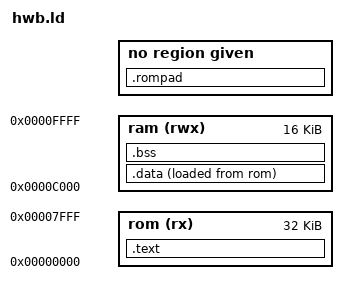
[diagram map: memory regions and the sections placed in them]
/* hwb.ld -- HWB profile (ADR 0013) for the code-banking test:
 *   0x0000-0x7FFF  fixed ROM: reset, code not in a bank, stubs, .rodata,
 *                  the ROM copy of .data
 *   0x8000-0xBFFF  bank window (banks.ld, generated by cosmac_bank.py)
 *   0xC000-0xFFFF  RAM
 * The ROM image is the fixed part (padded to 32 KiB) followed by the banks.
 */

OUTPUT_ARCH(cdp1802)
ENTRY(__start)

MEMORY
{
  rom (rx)  : ORIGIN = 0x0000, LENGTH = 32K
  ram (rwx) : ORIGIN = 0xC000, LENGTH = 16K
}

SECTIONS
{
  .text :
  {
    KEEP(*(.reset))
    *(.text .text.*)
    *(.rodata .rodata.*)
  } > rom

  .data :
  {
    _sdata = .;
    *(.data .data.*)
    _edata = .;
  } > ram AT > rom

  _eronly = LOADADDR(.data);

  .bss (NOLOAD) :
  {
    _sbss = .;
    *(.bss .bss.*)
    *(COMMON)
    _ebss = .;
  } > ram

  /* Pad the fixed ROM to 32 KiB so that bank 0 starts at image offset
   * 0x8000.
   */

  .rompad _eronly + SIZEOF(.data) : AT(_eronly + SIZEOF(.data))
  {
    BYTE(0xff)
    FILL(0xff)
    . = 0x8000 - (_eronly + SIZEOF(.data));
  }

  INCLUDE banks.ld

  __sim1802_rom_end = 0x8000;
  __sim1802_banks = __cosmac_banks;
  ASSERT(_eronly + SIZEOF(.data) <= 0x8000, "HWB: fixed ROM overflow")
}
